# USB_USB2SS_GBL_3100C100h register map
Vendor: Texas Instruments
Peripheral module from a debugger description file (folder am62L).
Registers are 32-bit, read-write, reset 0x0 unless marked. A register's access mark holds for its fields unless they carry their own. Offsets are as the file gives them; lines under a group give offsets from that group; [hi:lo] are bit positions; {n}, {i} and the like mark numbered series; 'fields as' and 'values as' point back to an identical list; <NAME> marks a mode.

## USB2SS_GBL (part 1 of 4)
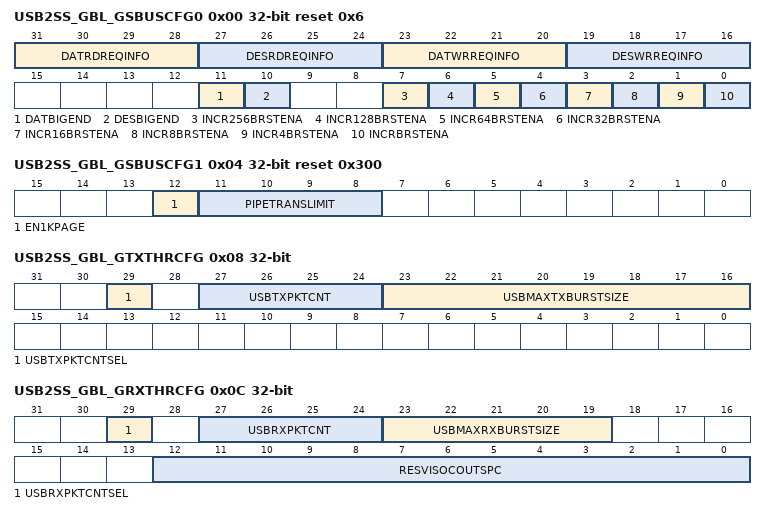
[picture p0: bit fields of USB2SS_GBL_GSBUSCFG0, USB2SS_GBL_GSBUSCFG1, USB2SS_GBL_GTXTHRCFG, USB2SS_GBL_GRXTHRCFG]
0x00 USB2SS_GBL_GSBUSCFG0 access per field reset 0x6 — Global SoC Bus Configuration Register 0This register configures system bus DMA options for the master bus, which may be configured as AHB, AXI, or Native. Options include burst length and cache type (bufferable/posted, cacheable/snoop, and so on). The application can program this register upon power-on, or a change in mode of operation after the DMA engine is halted.xHCI Register Power-On Value:If you are using a standard xHCI host driver, make sure to set the register's power-on value during coreConsultant configuration (DWC_USB3_GSBUSCFG0_INIT parameter) because the standard xHCI driver does not access this register.For more details on this register, refer to the following sections: - 'Usage of Global SoC Bus Configuration Register 0 (GSBUSCFG0)' section in the Programming Guide - 'System Bus Interface' section in the Databook
  [31:28] DATRDREQINFO rw — DATRDREQINFO AHB-prot/AXI-cache/OCP-ReqInfo for Data Read [DatRdReqInfo] Input to BUS-GM. Reset Source: rst_mod_g_rst_n
  [27:24] DESRDREQINFO rw — DESRDREQINFOAHB-prot/AXI-cache/OCP-ReqInfo for Descriptor Read [DesRdReqInfo].Input to BUS-GM. Reset Source: rst_mod_g_rst_n
  [23:20] DATWRREQINFO rw — DATWRREQINFOAHB-prot/AXI-cache/OCP-ReqInfo for Data Write [DatWrReqInfo]. Input to BUS-GM. Reset Source: rst_mod_g_rst_n
  [19:16] DESWRREQINFO rw — DESWRREQINFOAHB-prot/AXI-cache/OCP-ReqInfo for Descriptor Write [DesWrReqInfo] Input to BUS-GM. Reset Source: rst_mod_g_rst_n
  [11] DATBIGEND rw — Data Access is Big Endian This bit controls the endian mode for data accesses. - Little-endian [default]. - Big-endian. In big-endian mode, DMA access [both read and write] for packet data a Byte Invariant Big-Endian mode [see 'Little-Endian and Big-Endian' section in the User Guide].Note: Since AXI requires byte invariant endianness, setting DescBigend and DatBigEnd to one causes an address invariant transform to be applied, which is not appropriate. See section 9.3 and 9.4 of the AMBA AXI Specification. Hence for an AXI master [DWC_USB3_MBUS_TYPE=1], this bit must be set to zero. Reset Source: rst_mod_g_rst_n
  [10] DESBIGEND rw — Descriptor Access is Big EndianThis bit controls the endian mode for descriptor accesses. - Little-endian [default] - Big-endian In big-endian mode, DMA access [both read and write] for descriptors uses a Byte Invariant Big-Endian mode [see 'Little-Endian and Big-Endian' section in the User Guide. Data is considered as 'embedded data' in the descriptors in the following cases: - Device mode: The buffer pointer of a Setup TRB points to the Setup TRB itself. - Host mode: The Immediate Data [IDT] bit in a Transfer TRB is set to 1.In device mode, if the system uses different endian modes for descriptor and data, software must not use 'embedded' data.In host mode, if the system uses different endian modes for data and descriptors, the controller treats 'embedded data' as descriptor [not as data] in terms of endian mode handling. If this is not the expectation of the system, the software must manipulate the 'embedded data' accordingly.Note: Since AXI requires byte invariant endianness, setting DescBigend and DatBigEnd to one causes an address invariant transform to be applied, which is not appropriate. See section 9.3 and 9.4 of the AMBA AXI Specification. Hence for an AXI master [DWC_USB3_MBUS_TYPE=1], this bit must be set to zero. Reset Source: rst_mod_g_rst_n
  [7] INCR256BRSTENA rw — INCR256 Burst Type EnableInput to BUS-GM. For the AHB/AXI configuration, if software set this bit to 1, the AHB/AXI master uses INCR to do the 256-beat burst. Reset Source: rst_mod_g_rst_n
  [6] INCR128BRSTENA rw — INCR128 Burst Type EnableInput to BUS-GM.For the AHB/AXI configuration, if software set this bit to 1, the AHB/AXI master uses INCR to do the 128-beat burst. Reset Source: rst_mod_g_rst_n
  [5] INCR64BRSTENA rw — INCR64 Burst Type Enable - Input to BUS-GM. For the AHB/AXI configuration, if software set this bit to 1, the AHB/AXI master uses INCR to do the 64-beat burst. Reset Source: rst_mod_g_rst_n
  [4] INCR32BRSTENA rw — INCR32 Burst Type EnableInput to BUS-GM.For the AHB/AXI configuration, if software set this bit to 1, the AHB/AXI master uses INCR to do the 32-beat burst. Reset Source: rst_mod_g_rst_n
  [3] INCR16BRSTENA rw — INCR16 Burst Type EnableInput to BUS-GM. For the AHB/AXI configuration, if software set this bit to '1', the AHB/AXI master uses INCR to do the 16-beat burst. Reset Source: rst_mod_g_rst_n
  [2] INCR8BRSTENA rw — INCR8 Burst Type EnableInput to BUS-GM. For the AHB/AXI configuration, if software set this bit to '1', the AHB/AXI master uses INCR to do the 8-beat burst. Reset Source: rst_mod_g_rst_n
  [1] INCR4BRSTENA rw — INCR4 Burst Type EnableInput to BUS-GM. For the AXI configuration, when this bit is enabled the controller is allowed to do bursts of beat length 1, 2, and 4. It is highly recommended that this bit is enabled to prevent descriptor reads and writes from being broken up into separate transfers. Reset Source: rst_mod_g_rst_n
  [0] INCRBRSTENA rw — Undefined Length INCR Burst Type Enable [INCRBrstEna]Input to BUS-GM. This bit determines the set of burst lengths the master interface uses. It works in conjunction with the GSBUSCFG0[7:1] enables [INCR256/128/64/32/16/8/4].0: INCRX burst modeHBURST [for AHB configurations] and ARLEN/AWLEN [for AXI configurations] do not use INCR except in case of non-aligned burst transfers. In the case of address-aligned transfers, they use only the following burst lengths: - 1 - 2, 4 [if GSBUSCFG0.INCR4BrstEna = 1] - 8 [if GSBUSCFG0.INCR8BrstEna = 1] - 16 [if GSBUSCFG0.INCR16BrstEna = 1] - 32 [if GSBUSCFG0.INCR32BrstEna = 1] - 64 [if GSBUSCFG0.INCR64BrstEna = 1] - 128 [if GSBUSCFG0.INCR128BrstEna = 1] - 256 [if GSBUSCFG0.INCR256BrstEna = 1]Note: - In case of non-address-aligned transfers, INCR may get generated at the beginning and end of the transfers to align the address boundaries, even though INCR is disabled. - In AHB mode, if INCRX burst mode is enabled, but none of the supported INCRx bursts bits are enabled, then the controller will perform [undefined length] INCR bursts.1: INCR [undefined length] burst mode - AHB configurations: HBURST uses SINGLE or INCR of any length with handling 1KB boundary breakup. - AXI configurations: ARLEN/AWLEN uses any length less than or equal to the largest-enabled burst length of INCR32/64/128/256.For cache line-aligned applications, this bit is typically set to 0 to ensure that the master interface uses only power-of-2 burst lengths [as enabled via GSBUSCFG0[7:0]]. Reset Source: rst_mod_g_rst_n
0x04 USB2SS_GBL_GSBUSCFG1 reset 0x300 — Global SoC Bus Configuration Register 1xHCI Register Power-On Value:If you are using a standard xHCI host driver, make sure to set the register's power-on value during coreConsultant configuration (DWC_USB3_GSBUSCFG1_INIT parameter) because the standard xHCI driver does not access this register.For more details on this register, refer to 'System Bus Interface' section in the Databook.
  [12] EN1KPAGE — 1k Page Boundary EnableBy default [this bit is disabled] the AXI breaks transfers at the 4k page boundary. When this bit is enabled, the AXI master [DMA data] breaks transfers at the 1k page boundary. Reset Source: rst_mod_g_rst_n
  [11:8] PIPETRANSLIMIT — AXI Pipelined Transfers Burst Request LimitThe field controls the number of outstanding pipelined transfer requests the AXI master pushes to the AXI target. When the AXI master reaches this limit, it does not make any more requests on the AXI ARADDR and AWADDR buses until the associated data phases complete.This field is encoded as follows: - 'h0: 1 request - 'h1: 2 requests - 'h2: 3 requests - 'h3: 4 requests - ... - 'hF: 16 requests Reset Source: rst_mod_g_rst_n
0x08 USB2SS_GBL_GTXTHRCFG access per field — Global Tx Threshold Control RegisterFor more information on - Using this register, refer to 'Packet Threshold and Burst Features for High Latency Systems' section in the Databook. - Selecting values for the fields of this register, see the 'TX/RX Data FIFO Sizes and TX/RX Threshold Control Register Settings' section in the User Guide.Note: - GTXTHRCFG register is not applicable for Debug Target. - GTXTHRCFG register is not applicable in USB 2.0-only mode.
  [29] USBTXPKTCNTSEL rw — USB Transmit Packet Count EnableThis field enables/disables the USB transmission multi-packet thresholding: - 0: USB transmission multi-packet thresholding is disabled. the controller can start transmission on the USB after the entire [one full] packet has been fetched into the corresponding TXFIFO. - 1: USB transmission multi-packet thresholding is enabled. The controller can only start transmission on the USB after USB Transmit Packet Count amount of packets for the USB transaction [burst] are already in the corresponding TXFIFO. This mode is valid in both host and device modes. It is only used for SuperSpeed operation. Reset Source: rst_mod_g_rst_n
  [27:24] USBTXPKTCNT rw — USB Transmit Packet CountThis field specifies the number of packets that must be in the TXFIFO before the controller can start transmission for the corresponding USB transaction [burst]. This field is only valid when the USB Transmit Packet Count Enable field is set to one. Valid values are from 1 to 15.Note: - In device mode, if device controller does not have the TRBs for the number of packets or if it cannot fetch the TRBs because of high latency or switching between other endpoints, then it does not wait for the threshold number of packets. The threshold number of packets will be honored only when the TRBs are available in the controller for the number of packets before it starts the data fetch. - This field must be less than or equal to the USB Maximum TX Burst Size field. Reset Source: rst_mod_g_rst_n
  [23:16] USBMAXTXBURSTSIZE rw — USB Maximum TX Burst Size When UsbTxPktCntSel is one, this field specifies the Maximum Bulk OUT burst the controller can do. When the system bus is slower than the USB, TX FIFO can underrun during a long burst. User can program a smaller value to this field to limit the TX burst size that the controller can do. Host mode: It only applies to SS Bulk, Isochronous, and Interrupt OUT endpoints. Device mode: This value is not used in device mode, but users need to program a value when using the TX threshold feature to make sure that the value programmed in UsbTxPktCnt is less than this value.Valid values are from 1 to 16. Reset Source: rst_mod_g_rst_n
0x0C USB2SS_GBL_GRXTHRCFG — Global Rx Threshold Control RegisterIn a normal case, a Tx burst starts as soon as one packet is prefetched. an Rx burst starts as soon as 1-packet space is available. This works well as long as the system bus is faster than the USB 3.0 bus (a 1024-bytes packet takes ~2.2 microseconds on the USB bus in SS mode). If the system bus latency is larger than 2.2 microseconds to access a 1024-byte packet, then starting a burst on 1-packet condition leads to an early abort of the burst causing unnecessary performance reduction. To avoid underrun and overrun during the burst, in a high-latency bus system (like USB), threshold and burst size control is provided through GTXTHRCFG and GRXTHRCFG registers. Bit [29] of the GTXTHRCFG and GRXTHRCFG registers enables this feature.For more information on - Using this register, refer to 'Packet Threshold and Burst Features for High Latency Systems' section in the Databook. - Selecting values for the fields of this register, see the 'TX/RX Data FIFO Sizes and TX/RX Threshold Control Register Settings' section in the User Guide.Note: - GRXTHRCFG register is not applicable for Debug Target. - There is an issue when ACK TP with NumP=0 followed by ACK TP with NumP=1 without ERDY TP sent by the device controller during a burst bulk OUT transfer. This may cause third-party USB 3.0 host controllers to keep waiting for the ERDY TP.The USB 3.0 specification states that 'When an endpoint is not in a flow control condition, it shall not send an ERDY TP unless the endpoint is a Bulk endpoint that supports streams.' In this case, after the device sent the ACK TP (nump=1), the endpoint was not in the flow control, so it did not send an ERDY.The device would have sent ERDY if the next OUT packet was not received. When the next OUT packet was received, at that time there was enough buffer space to accept it, so the device accepted the packet by informing host that it is not no longer in the flow control. The Host should wait for the responses for all the OUT packets to return and then decide if the endpoint is still in flow control or not.The USB 3.1 specification supersedes all the USB 3.0 specification. The errata states that 'If the host continues, or resumes, transactions to an endpoint, the endpoint shall re-evaluate its flow control state and respond appropriately.' However, there are no ECNs on the USB 3.0 for this issue.To work around this issue, the Global Rx Threshold mode must be disable by setting GRXTHRCFG.UsbRxPktCntSel=0. Instead, software can program the DCFG.NUMP mode (where fixed NUMP is transmitted always) instead of the RX threshold based nump mode to prevent the device from sending ACK TP with NumP=0. The NUMP in the ACK TP is the minimum value of (DCFG.NUMP, bMaxBurstSize) for each endpoint.
  [29] USBRXPKTCNTSEL — USB Receive Packet Count EnableThis field enables/disables the USB reception multi-packet thresholding: - 0: The controller can only start reception on the USB when the RX FIFO has space for at least one packet. - 1: The controller can only start reception on the USB when the RX FIFO has space for at least UsbRxPktCnt amount of packets. This mode is valid in both host and device mode. It is only used for SuperSpeed. In device mode, - Setting this bit to 1 also enables the functionality of reporting NUMP in the ACK TP based on the RX FIFO space instead of reporting a fixed NUMP derived from DCFG.NUMP for non-control endpoints. - If you are using external buffer control [EBC] feature, disable this mode by setting UsbRxPktCntSel to 0. Reset Source: rst_mod_g_rst_n
  [27:24] USBRXPKTCNT — USB Receive Packet CountIn host mode, this field specifies the space [in terms of the number of packets] that must be available in the RX FIFO before the controller can start the corresponding USB RX transaction [burst]. In device mode, this field specifies the space [in terms of the number of packets] that must be available in the RX FIFO before the controller can send ERDY for a flow-controlled endpoint.This field is valid only when the USB Receive Packet Count Enable field is set to 1. The valid values for this field are from 1 to 15. Note: This field must be less than or equal to the USB Maximum Receive Burst Size field. Reset Source: rst_mod_g_rst_n
  [23:19] USBMAXRXBURSTSIZE — USB Maximum Receive Burst SizeIn host mode, this field specifies the Maximum Bulk IN burst the DWC_usb3 controller can perform. When the system bus is slower than the USB, RX FIFO can overrun during a long burst. You can program a smaller value to this field to limit the RX burst size that the controller can perform. It only applies to SS Bulk, Isochronous, and Interrupt IN endpoints in the host mode. In device mode, this field specifies the NUMP value that is sent in ERDY for an OUT endpoint. The programmed value should not exceed the RXFIFO size.This field is valid only when UsbRxPktCntSel is one. The valid values for this field are from 1 to 16. Reset Source: rst_mod_g_rst_n
  [12:0] RESVISOCOUTSPC — Space reserved in Rx FIFO for ISOC OUTIn host mode, this field is not applicable and must be programmed to 0. In device mode, this value represents the amount of space to be reserved for ISOC OUT packets. The value to be programmed should be chosen so as to ensure that non ISOC packets are not completely dropped. If no space needs to be reserved for ISOC OUT packets, program this field to 0.This field is valid only in device mode. The maximum configurable depth of RX FIFO is 8192. Therefore, this field is 13 bits wide.The value of space reserved is in terms of DWC_USB3_MDWIDTH.For SS, the space reservation is always rounded off to the nearest packet boundary. Therefore, it is always recommended to program a value corresponding to MPS or its multiples.For HS/FS, the space reservation is the actual value.Note: For SS, reserve space for ISOC when the Rx FIFO space can accommodate two MPS or more. Otherwise, this may result in degraded performance for non-ISOC packets. If the space is entirely allocated for ISOC, the non-ISOC packets will be completely dropped. To help you decide during the time of configuring the controller, refer to the 'Device-Mode Receive Path' section in the Databook. Reset Source: rst_mod_g_rst_n
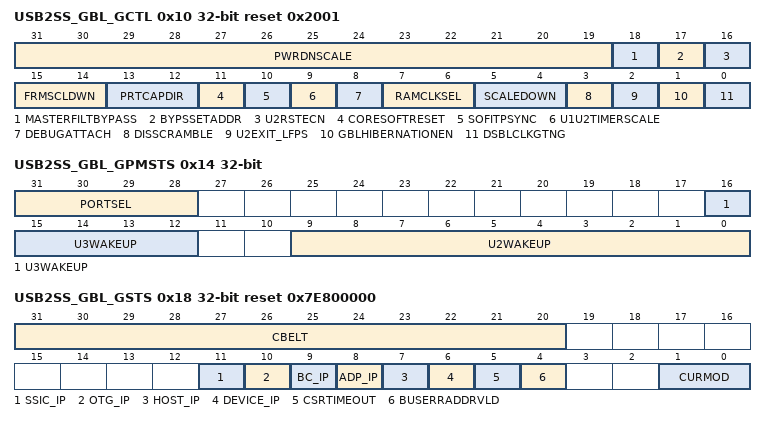
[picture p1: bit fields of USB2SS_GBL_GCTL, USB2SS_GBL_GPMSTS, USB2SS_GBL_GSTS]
0x10 USB2SS_GBL_GCTL access per field reset 0x2001 — Global Core Control RegisterRefer to <workspace>/src/DWC_usb3_params.v for details on DWC_USB3_GCTL_INIT.Note: When Hibernation is not enabled, you can write any value to GblHibernationEn. It always returns 0 when read.
  [31:19] PWRDNSCALE rw — Power Down Scale [PwrDnScale]The USB3 suspend_clk input replaces pipe3_rx_pclk as a clock source to a small part of the USB3 controller that operates when the SS PHY is in its lowest power [P3] state, and therefore does not provide a clock.The Power Down Scale field specifies how many suspend_clk periods fit into a 16 kHz clock period. When performing the division, round up the remainder.For example, when using an 8-bit/16-bit/32-bit PHY and 25-MHz Suspend clock,Power Down Scale = 25000 kHz/16 kHz = 13'd1563 [rounder up]Note: - Minimum Suspend clock frequency is 32 kHz - Maximum Suspend clock frequency is 125 MHzThe LTSSM uses Suspend clock for 12-ms and 100-ms timers during suspend mode. According to the USB 3.0 specification, the accuracy on these timers is 0% to +50%. - 12 ms + 0~+50% accuracy = 18 ms [Range is 12 ms - 18 ms] - 100 ms + 0~+50% accuracy = 150 ms [Range is 100 ms - 150 ms].The suspend clock accuracy requirement is: - [12,000/62.5] * [GCTL[31:19]] * actual suspend_clk_period must be between 12,000 and 18,000 - [100,0000/62.5] * [GCTL[31:19]] * actual suspend_clk_period must be between 100,000 and 150,000For example, if your suspend_clk frequency varies from 7.5 MHz to 10.5MHz, then the value needs to programmed is:Power Down Scale = 10500/16 = 657 [rounded up. and fastest frequency used]. Reset Source: rst_mod_g_rst_n
  [18] MASTERFILTBYPASS rw — Master Filter BypassWhen this bit is set to 1'b1, irrespective of the parameter DWC_USB3_EN_BUS_FILTERS chosen, all the filters in the DWC_usb3_filter module are bypassed. The double synchronizers to mac_clk preceding the filters are also bypassed. For enabling the filters, this bit must be 1'b0. Reset Source: rst_mod_g_rst_n
  [17] BYPSSETADDR rw — Bypass SetAddress in Device Mode. When BYPSSETADDR bit is set, the device controller uses the value in the DCFG[DevAddr] bits directly for comparing the device address in the tokens. For simulation, you can use this feature to avoid sending an actual SET ADDRESS control transfer on the USB, and make the device controller respond to a new address.When the xHCI Debug capability is enabled and this bit is set, the Debug Target immediately enters the configured state without requiring the Debug Host to send a SetAddress or SetConfig request.Note: You can set this bit for simulation purposes only. In the actual hardware, this bit must be set to 1'b0. Reset Source: rst_mod_g_rst_n
  [16] U2RSTECN rw — U2RSTECNIf the SuperSpeed connection fails during POLL or LMP exchange, the device connects at non-SS mode. If this bit is set, then device attempts three more times to connect at SS, even if it previously failed to operate in SS mode. For each attempt, the device checks receiver termination eight times.From 2.60a release, this bit controls whether to check for Rx.Detect eight times or one time for every attempt. Device controller on USB 2.0 reset checks for receiver termination eight times per attempt if this bit is set to zero, or only once per attempt if the bit is set to one.Note: This bit is applicable only in device mode. Reset Source: rst_mod_g_rst_n
  [15:14] FRMSCLDWN rw — FRMSCLDWNThis field scales down device view of a SOF/USOF/ITP duration.For SS/HS mode: - Value of 2'h3 implements interval to be 15.625 us - Value of 2'h2 implements interval to be 31.25 us - Value of 2'h1 implements interval to be 62.5 us - Value of 2'h0 implements interval to be 125usFor FS mode, the scale-down value is multiplied by 8.When xHCI Debug Capability is enabled, this field also scales down the MaxPacketSize of the IN and OUT bulk endpoint to allow more traffic during simulation. It can only be changed from a non-zero value during simulation. - 2'h0: 1024 bytes - 2'h1: 512 bytes - 2'h2: 256 bytes - 2'h3: 128 bytes Reset Source: rst_mod_g_rst_n
  [13:12] PRTCAPDIR rw — PRTCAPDIR: Port Capability Direction [PrtCapDir] - 2'b01: for Host configurations - 2'b10: for Device configurationsNote: For static Host-only/Device-only applications, use DRD Host or DRD Device mode. The combination of GCTL.PrtCapDir=2'b11 with SRP and HNP/RSP disabled is not recommended for these applications.The sequence for switching modes in DRD configuration is as follows: Switching from Device to Host:1. Reset the controller using GCTL[11] [CoreSoftReset].2. Set GCTL[13:12] [PrtCapDir] to 2'b01 [Host mode].3. Reset the host using USBCMD.HCRESET. Switching from Host to Device:1. Reset the controller using GCTL[11] [CoreSoftReset].2. Set GCTL[13:12] [PrtCapDir] to 2'b10 [Device mode].3. Reset the device by setting DCTL[30] [CSftRst]. Reset Source: rst_mod_g_rst_n
  [11] CORESOFTRESET rw — Core Soft Reset [CoreSoftReset] - 1'b0 - No soft reset - 1'b1 - Soft reset to controllerClears the interrupts and all the CSRs except the following registers: - GCTL - GUCTL - GSTS - GSNPSID - GGPIO - GUID - GUSB2PHYCFGn registers - GUSB3PIPECTLn registers - DCFG - DCTL - DEVTEN - DSTSWhen you reset PHYs [using GUBS3PHYCFG or GUSB3PIPECTL registers], you must keep the controller in reset state until PHY clocks are stable. This controls the bus, ram, and mac domain resets. Refer to the 'Reset Generation' section in the Databook.Note: This bit is for debug purposes only. Use USBCMD.HCRESET in xHCI Mode and DCTL.SoftReset in device mode for soft reset. Programming this field with random data will reset the internal logic of the host controller. Due to this side effect Bit Bash register testing is not recommended. Reset Source: rst_mod_g_rst_n
  [10] SOFITPSYNC rw — SOFITPSYNCIf this bit is set to '0' operating in host mode, the controller keeps the UTMI/ULPI PHY on the first port in a non-suspended state whenever there is a SuperSpeed port that is not in Rx.Detect, SS.Disable and U3. If this bit is set to '1' operating in host mode, the controller keeps the UTMI/ULPI PHY on the first port in a non-suspended state whenever the other non-SuperSpeed ports are not in a suspended state. This feature is useful because it saves power by suspending UTMI/ULPI when SuperSpeed only is active, and it helps resolve when the PHY does not transmit a host resume unless it is placed in suspend state. This bit must be programmed as a part of initialization at power-on reset, and must not be dynamically changed afterwards. Note: - USB2PHYCFGn[6].PhySusp eventually decides to put the UTMI/ULPI PHY in to suspend state. In addition, when this bit is set to '1', the controller generates ITP from the ref_clk based counter. Otherwise, ITP and SOF are generated from utmi/ulpi_clk[0] based counter. To program the reference clock period inside the controller, refer to GUCTL[31:22].REFCLKPER. - This feature is valid in Host and DRD configurations and used only in Host mode operation. - If you never use this feature or the GFLADJ.GFLADJ_REFCLK_LPM_SEL, the minimum frequency for the ref_clk can be as low as 32KHz. You can connect the suspend_clk [as low as 32 KHz] to the ref_clk. - If you plan to enable hardware-based LPM or software-based LPM [PORTPMSC. HLE=1], then you cannot use this feature. Turn off this feature by setting this bit to '0' and use the GFLADJ.GFLADJ_REFCLK_LPM_SEL feature. - If you set this bit to '1', the GUSB2PHYCFG.U2_FREECLK_EXISTS bit and the DWC_USB3_FREECLK_USB2_EXIST parameter must be set to '0'.Program this bit to 0 if the controller is intended to be operated in USB 3.0 mode. Reset Source: rst_mod_g_rst_n
  [9] U1U2TIMERSCALE rw — Disable U1/U2 timer Scaledown [U1U2TimerScale]. If set to '1' along with GCTL[5:4] [ScaleDown] = 2'bX1, disables the scale down of U1/U2 inactive timer values. This is for simulation mode only. Reset Source: rst_mod_g_rst_n
  [8] DEBUGATTACH rw — Debug AttachWhen this bit is set, - SS Link proceeds directly to the Polling link state [after RUN/STOP in the DCTL register is asserted] without checking remote termination. - Link LFPS polling timeout is infinite. - Polling timeout during TS1 is infinite [in case link is waiting for TXEQ to finish]. Reset Source: rst_mod_g_rst_n
  [7:6] RAMCLKSEL rw — RAM Clock Select [RAMClkSel] - 2'b00: bus clock - 2'b01: pipe clock [Only used in device mode] - 2'b10: In device mode , pipe/2 clock.In Host mode, controller switches ram_clk between pipe/2 clock, mac2_clk and bus_clk based on the status of the U2/U3 ports - 2'b11: In device mode, selects mac2_clk as ram_clk [when 8-bit UTMI or ULPI used. Not supported in 16-bit UTMI mode] In Host mode, controller switches ram_clk between pipe_clk, mac2_clk and bus_clk based on the status of the U2/U3 ports. In device mode, upon a USB reset and USB disconnect, the hardware clears these bits to 2'b00. For more information on how to select the RAM clock, see the 'Clock Generation and Clock Tree Synthesis [CTS] Requirements' section in the Databook. Note: - In device mode, if you set RAMClkSel to 2'b11 [mac2_clk], the controller internally switches the ram_clk to bus_clk when the link state changes to Suspend [L2 or L3], and switches the ram_clk back to mac2_clk when the link state changes to resume or U2. - In host mode, if a value of 2/3 is chosen, then controller switches ram_clk between bus_clk, mac2_clk and pipe_clk, pipe_clk/2, based on the state of the U2/U3 ports. For example, if only the U2 port is active and the U3 ports are suspended, then the ram_clk is switched to mac2_clk. When only the U3 ports are active and the U2 ports are suspended, the controller internally switches the ram_clk to pipe3 clock and when all U2 and U3 ports are suspended, it switches the ram_clk to bus_clk. This allows decoupling the ram_clk from the bus_clk, and depending on the bandwidth requirement allows the bus_clk to be run at a lower frequency than the ram_clk requirements. The bus_clk frequency still cannot be less than 60MHz in host mode, and this is not verified.A value of 2 can be chosen only if the pipe data width is 8 or 16 bits. In this case the when the ram_clk is switched to pipe_clk, it uses pipe_clk/2 instead of pipe_clk. If a value of 3 is chosen for RAMClkSel, then when ram_clk is switched to pipe_clk, then pipe_clk is used without any divider. - In device mode, when RAMClkSel != 2'b00, the bus_clk_early frequency can be a minimum of 1 MHz. This is tested in simulation and also in hardware with Linux, Microsoft Windows 8, and MCCI Windows7 host drivers. Only control and non periodic transfers are supported when bus_clk is 1 MHz. For periodic applications, the bus_clk_early minimum frequency is higher depending on your application and SoC bus. Even though 1 MHz has been tested with standard host drivers, Synopsys recommends 5 MHz minimum for ASIC designs to provide a margin or at least have a backup option to increase the bus_clk frequency to 5 MHz if needed.Programming this field with random data will cause side effect. Bit Bash register testing is not recommended. Reset Source: rst_mod_g_rst_n
  [5:4] SCALEDOWN rw — Scale-Down Mode [ScaleDown]When Scale-Down mode is enabled for simulation, the controller uses scaled-down timing values, resulting in faster simulations.When Scale-Down mode is disabled, actual timing values are used. This is required for hardware operation.HS/FS/LS Modes - 2'b00: Disables all scale-downs. Actual timing values are used. - 2'b01: Enables scale-down of all timing values except Device mode suspend and resume. These include Speed enumeration, HNP/SRP, and Host mode suspend and resume - 2'b10: Enables scale-down of Device mode suspend and resume timing values only. - 2'b11: Enables bit 0 and bit 1 scale-down timing values.SS Mode - 2'b00: Disables all scale-downs. Actual timing values are used. - 2'b01: Enables scaled down SS timing and repeat values including: [1] Number of TxEq training sequences reduce to 8. [2] LFPS polling burst time reduce to 256 nS. [3] LFPS warm reset receive reduce to 30 uS. Refer to the rtl_vip_scaledown_mapping.xls file under <workspace>/sim/SoC_sim directory for the complete list. - 2'b10: No TxEq training sequences are sent. Overrides Bit 4. - 2'b11: Enables bit 0 and bit 1 scale-down timing values. Reset Source: rst_mod_g_rst_n
  [3] DISSCRAMBLE rw — Disable Scrambling [DisScramble] Transmit request to Link Partner on next transition to Recovery or Polling. Reset Source: rst_mod_g_rst_n
  [2] U2EXIT_LFPS rw — U2EXIT_LFPSIf this bit is, - 0: the link treats 248ns LFPS as a valid U2 exit. - 1: the link waits for 8us of LFPS before it detects a valid U2 exit.This bit is added to improve interoperability with a third-party host/device controller. This host/device controller in U2 state while performing receiver detection generates an LFPS glitch of about 4ms duration. This causes the host/device to exit from U2 state because the LFPS filter value is 248ns. With the new functionality enabled, the host/device can stay in U2 while ignoring this glitch from the host/device controller.This bit is applicable for both host and device controller. This bit is added to improve interoperability with a third party host controller. This host controller in U2 state while performing receiver detection generates an LFPS glitch of about 4ms duration. This causes the device to exit from U2 state because the LFPS filter value is 248ns. With the new functionality enabled, the device can stay in U2 while ignoring this glitch from the host controller. Reset Source: rst_mod_g_rst_n
  [1] GBLHIBERNATIONEN ro — GblHibernationEnThis bit enables hibernation at the global level. If hibernation is not enabled through this bit, the PMU immediately accepts the D0->D3 and D3->D0 power state change requests, but does not save or restore any controller state.In addition, the PMUs never drive the PHY interfaces and let the controller continue to drive the PHY interfaces. Reset Source: rst_mod_g_rst_n
  [0] DSBLCLKGTNG rw — Disable Clock Gating [DsblClkGtng]This bit is set to 1 and the controller is in Low Power mode, internal clock gating is disabled.You can set this bit to 1'b1 after Power On Reset. Reset Source: rst_mod_g_rst_n
0x14 USB2SS_GBL_GPMSTS access per field — Global Power Management Status RegisterThis debug register gives information on which event caused the hibernation exit. It provides internal status and state machine information, and is for Synopsys use only for debugging purposes.This register is not applicable in USB 2.0-only mode.
  [31:28] PORTSEL wo — Global Power Management Status Register, PortSelThis field selects the port number. Reset Source: rst_mod_g_rst_n
  [16:12] U3WAKEUP ro — U3WakeupThis field gives the following USB 3.0 port wakeup conditions: - Bit [12]: Overcurrent Detected - Bit [13]: Resume Detected - Bit [14]: Connect Detected - Bit [15]: Disconnect Detected - Bit [16]: Last Connection State Reset Source: rst_mod_g_rst_n
  [9:0] U2WAKEUP ro — U2WakeupThis field indicates the following USB 2.0 port wakeup conditions: - Bit [0]: Overcurrent Detected - Bit [1]: Resume Detected - Bit [2]: Connect Detected - Bit [3]: Disconnect Detected - Bit [4]: Last Connection State - Bit [5]: ID Change Detected - Bit [6]: SRP Request Detected - Bit [7]: ULPI Interrupt Detected - Bit [8]: USB Reset Detected - Bit [9]: Resume Detected Changed Reset Source: rst_mod_g_rst_n
0x18 USB2SS_GBL_GSTS access not given reset 0x7E800000 — Global Status Register
  [31:20] CBELT ro — Current BELT ValueIn Host mode, this field indicates the minimum value of all received device BELT values and the BELT value that is set by the Set Latency Tolerance Value command. Reset Source: rst_mod_g_rst_n
  [11] SSIC_IP ro — This field is not used. Reset Source: rst_mod_g_rst_n
  [10] OTG_IP ro — This field is not used. Reset Source: rst_mod_g_rst_n
  [9] BC_IP ro — Battery Charger Interrupt PendingThis field indicates that there is a pending interrupt pertaining to BC in BCEVT register. Reset Source: rst_mod_g_rst_n
  [8] ADP_IP ro — This field is not used. Reset Source: rst_mod_g_rst_n
  [7] HOST_IP ro — Host Interrupt Pending:This field indicates that there is a pending interrupt pertaining to xHC in the Host event queue. Reset Source: rst_mod_g_rst_n
  [6] DEVICE_IP ro — Device Interrupt PendingThis field indicates that there is a pending interrupt pertaining to peripheral [device] operation in the Device event queue. Reset Source: rst_mod_g_rst_n
  [5] CSRTIMEOUT — CSR TimeoutWhen this bit is 1'b1, it indicates that the software performed a write or read to a controller register that could not be completed within DWC_USB3_CSR_ACCESS_TIMEOUT bus clock cycles [default: h1FFFF]. Reset Source: rst_mod_g_rst_n (access R/W1TC)
  [4] BUSERRADDRVLD — Bus Error Address Valid [BusErrAddrVld]Indicates that the GBUSERRADDR register is valid and reports the first bus address that encounters a bus error.Note: Only supported in AHB and AXI configurations. Reset Source: rst_mod_g_rst_n (access R/W1TC)
  [1:0] CURMOD ro — Current Mode of Operation [CurMod]Indicates the current mode of operation: - 2'b00: Device mode - 2'b01: Host mode Reset Source: rst_mod_g_rst_n
